# spi_controller: IP-XACT component
VLNV accellera.org:peripherals:spi_controller:1.0

## Address spaces and blocks
SPI_MMAP.SPI_REGS: base 0x0, range 0x1000, width 32

## Registers
Registers are 32-bit, read-write, no defined reset value unless marked. A register's access mark holds for its fields unless they carry their own. Offsets are from the block's base; lines under a group give offsets from that group; [hi:lo] are bit positions; {n}, {i} and the like mark numbered series; 'fields as' and 'values as' point back to an identical list; <NAME> marks a mode.

## SPI_MMAP.SPI_REGS
Base 0x00000000
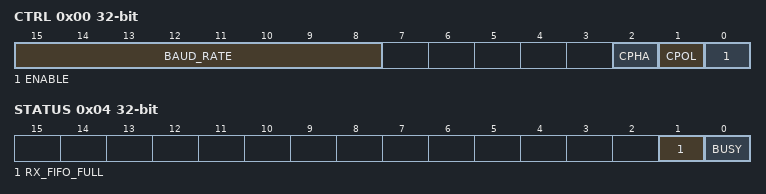
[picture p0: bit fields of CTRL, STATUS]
0x00 CTRL — SPI Control Register
  [15:8] BAUD_RATE — Prescaler Divisor
  [2] CPHA — Clock Phase
  [1] CPOL — Clock Polarity
  [0] ENABLE — SPI Core Enable
0x04 STATUS ro — SPI Status Register
  [1] RX_FIFO_FULL — Receive FIFO Full
  [0] BUSY — SPI Transfer Active
